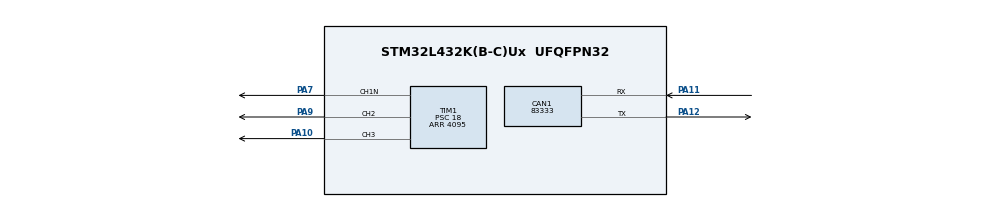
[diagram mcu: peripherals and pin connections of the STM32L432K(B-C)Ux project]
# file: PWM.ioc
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CAN1.CalculateBaudRate=83333
CAN1.CalculateTimeBit=12000
CAN1.CalculateTimeQuantum=4000.0
Mcu.Family=STM32L4
Mcu.Name=STM32L432K(B-C)Ux
Mcu.Package=UFQFPN32
NVIC.PriorityGroup=NVIC_PRIORITYGROUP_4
PA10.Signal=S_TIM1_CH3
PA11.Mode=CAN_Activate
PA11.Signal=CAN1_RX
PA12.Mode=CAN_Activate
PA12.Signal=CAN1_TX
PA7.Mode=PWM Generation1 CH1N
PA7.Signal=TIM1_CH1N
PA9.Signal=S_TIM1_CH2
ProjectManager.HeapSize=0x200
ProjectManager.StackSize=0x400
ProjectManager.TargetToolchain=STM32CubeIDE
RCC.APB1Freq_Value=4000000
RCC.APB1TimFreq_Value=4000000
RCC.APB2Freq_Value=4000000
RCC.APB2TimFreq_Value=4000000
RCC.HSE_VALUE=8000000
RCC.HSI48_VALUE=48000000
RCC.HSI_VALUE=16000000
RCC.MSI_VALUE=4000000
RCC.VCOOutputFreq_Value=32000000
SH.S_TIM1_CH2.0=TIM1_CH2,PWM Generation2 CH2
SH.S_TIM1_CH3.0=TIM1_CH3,PWM Generation3 CH3
TIM1.AutoReloadPreload=TIM_AUTORELOAD_PRELOAD_ENABLE
TIM1.Channel-PWM\ Generation1\ CH1N=TIM_CHANNEL_1
TIM1.Channel-PWM\ Generation2\ CH2=TIM_CHANNEL_2
TIM1.Channel-PWM\ Generation3\ CH3=TIM_CHANNEL_3
TIM1.Period=4095
TIM1.Prescaler=18
VP_TIM1_VS_ClockSourceINT.Mode=Internal
board=custom

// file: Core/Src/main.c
/* USER CODE BEGIN Header */
/**
  ******************************************************************************
  * @file           : main.c
  * @brief          : Main program body
  ******************************************************************************
  * @attention
  *
  * Copyright (c) 2023 STMicroelectronics.
  * All rights reserved.
  *
  * This software is licensed under terms that can be found in the LICENSE file
  * in the root directory of this software component.
  * If no LICENSE file comes with this software, it is provided AS-IS.
  *
  ******************************************************************************
  */
/* USER CODE END Header */
#include "main.h"

/* USER CODE BEGIN Includes */
#include "pwm.h"
#include "can.h"
/* USER CODE END Includes */

CAN_HandleTypeDef hcan1;

TIM_HandleTypeDef htim1;

void SystemClock_Config(void);
static void MX_GPIO_Init(void);
static void MX_TIM1_Init(void);
static void MX_CAN1_Init(void);

int main(void)
{

  /* MCU Configuration--------------------------------------------------------*/

  /* Reset of all peripherals, Initializes the Flash interface and the Systick. */
  HAL_Init();

  /* Configure the system clock */
  SystemClock_Config();

  /* Initialize all configured peripherals */
  MX_GPIO_Init();
  MX_TIM1_Init();
  MX_CAN1_Init();
  /* USER CODE BEGIN 2 */
  configure_CAN(&hcan1, CAN_ADDR_ACTIONNEUR_E);
  PWM_start_timer(TURBINE_CHANNEL);
  PWM_start_timer(SERVO_BALL_CHANNEL);
  PWM_start_timer(SERVO_BASKET_CHANNEL);

  /* USER CODE END 2 */

  /* Infinite loop */
  while (1)
  {

  }
}

void SystemClock_Config(void)
{
  RCC_OscInitTypeDef RCC_OscInitStruct = {0};
  RCC_ClkInitTypeDef RCC_ClkInitStruct = {0};

  /** Configure the main internal regulator output voltage
  */
  if (HAL_PWREx_ControlVoltageScaling(PWR_REGULATOR_VOLTAGE_SCALE1) != HAL_OK)
  {
    Error_Handler();
  }

  /** Initializes the RCC Oscillators according to the specified parameters
  * in the RCC_OscInitTypeDef structure.
  */
  RCC_OscInitStruct.OscillatorType = RCC_OSCILLATORTYPE_MSI;
  RCC_OscInitStruct.MSIState = RCC_MSI_ON;
  RCC_OscInitStruct.MSICalibrationValue = 0;
  RCC_OscInitStruct.MSIClockRange = RCC_MSIRANGE_6;
  RCC_OscInitStruct.PLL.PLLState = RCC_PLL_NONE;
  if (HAL_RCC_OscConfig(&RCC_OscInitStruct) != HAL_OK)
  {
    Error_Handler();
  }

  /** Initializes the CPU, AHB and APB buses clocks
  */
  RCC_ClkInitStruct.ClockType = RCC_CLOCKTYPE_HCLK|RCC_CLOCKTYPE_SYSCLK
                              |RCC_CLOCKTYPE_PCLK1|RCC_CLOCKTYPE_PCLK2;
  RCC_ClkInitStruct.SYSCLKSource = RCC_SYSCLKSOURCE_MSI;
  RCC_ClkInitStruct.AHBCLKDivider = RCC_SYSCLK_DIV1;
  RCC_ClkInitStruct.APB1CLKDivider = RCC_HCLK_DIV1;
  RCC_ClkInitStruct.APB2CLKDivider = RCC_HCLK_DIV1;

  if (HAL_RCC_ClockConfig(&RCC_ClkInitStruct, FLASH_LATENCY_0) != HAL_OK)
  {
    Error_Handler();
  }
}

static void MX_CAN1_Init(void)
{

  hcan1.Instance = CAN1;
  hcan1.Init.Prescaler = 16;
  hcan1.Init.Mode = CAN_MODE_NORMAL;
  hcan1.Init.SyncJumpWidth = CAN_SJW_1TQ;
  hcan1.Init.TimeSeg1 = CAN_BS1_1TQ;
  hcan1.Init.TimeSeg2 = CAN_BS2_1TQ;
  hcan1.Init.TimeTriggeredMode = DISABLE;
  hcan1.Init.AutoBusOff = DISABLE;
  hcan1.Init.AutoWakeUp = DISABLE;
  hcan1.Init.AutoRetransmission = DISABLE;
  hcan1.Init.ReceiveFifoLocked = DISABLE;
  hcan1.Init.TransmitFifoPriority = DISABLE;
  if (HAL_CAN_Init(&hcan1) != HAL_OK)
  {
    Error_Handler();
  }

}

static void MX_TIM1_Init(void)
{

  TIM_ClockConfigTypeDef sClockSourceConfig = {0};
  TIM_MasterConfigTypeDef sMasterConfig = {0};
  TIM_OC_InitTypeDef sConfigOC = {0};
  TIM_BreakDeadTimeConfigTypeDef sBreakDeadTimeConfig = {0};

  htim1.Instance = TIM1;
  htim1.Init.Prescaler = 18;
  htim1.Init.CounterMode = TIM_COUNTERMODE_UP;
  htim1.Init.Period = 4095;
  htim1.Init.ClockDivision = TIM_CLOCKDIVISION_DIV1;
  htim1.Init.RepetitionCounter = 0;
  htim1.Init.AutoReloadPreload = TIM_AUTORELOAD_PRELOAD_ENABLE;
  if (HAL_TIM_Base_Init(&htim1) != HAL_OK)
  {
    Error_Handler();
  }
  sClockSourceConfig.ClockSource = TIM_CLOCKSOURCE_INTERNAL;
  if (HAL_TIM_ConfigClockSource(&htim1, &sClockSourceConfig) != HAL_OK)
  {
    Error_Handler();
  }
  if (HAL_TIM_PWM_Init(&htim1) != HAL_OK)
  {
    Error_Handler();
  }
  sMasterConfig.MasterOutputTrigger = TIM_TRGO_RESET;
  sMasterConfig.MasterOutputTrigger2 = TIM_TRGO2_RESET;
  sMasterConfig.MasterSlaveMode = TIM_MASTERSLAVEMODE_DISABLE;
  if (HAL_TIMEx_MasterConfigSynchronization(&htim1, &sMasterConfig) != HAL_OK)
  {
    Error_Handler();
  }
  sConfigOC.OCMode = TIM_OCMODE_PWM1;
  sConfigOC.Pulse = 0;
  sConfigOC.OCPolarity = TIM_OCPOLARITY_HIGH;
  sConfigOC.OCNPolarity = TIM_OCNPOLARITY_HIGH;
  sConfigOC.OCFastMode = TIM_OCFAST_DISABLE;
  sConfigOC.OCIdleState = TIM_OCIDLESTATE_RESET;
  sConfigOC.OCNIdleState = TIM_OCNIDLESTATE_RESET;
  if (HAL_TIM_PWM_ConfigChannel(&htim1, &sConfigOC, TIM_CHANNEL_1) != HAL_OK)
  {
    Error_Handler();
  }
  if (HAL_TIM_PWM_ConfigChannel(&htim1, &sConfigOC, TIM_CHANNEL_2) != HAL_OK)
  {
    Error_Handler();
  }
  if (HAL_TIM_PWM_ConfigChannel(&htim1, &sConfigOC, TIM_CHANNEL_3) != HAL_OK)
  {
    Error_Handler();
  }
  sBreakDeadTimeConfig.OffStateRunMode = TIM_OSSR_DISABLE;
  sBreakDeadTimeConfig.OffStateIDLEMode = TIM_OSSI_DISABLE;
  sBreakDeadTimeConfig.LockLevel = TIM_LOCKLEVEL_OFF;
  sBreakDeadTimeConfig.DeadTime = 0;
  sBreakDeadTimeConfig.BreakState = TIM_BREAK_DISABLE;
  sBreakDeadTimeConfig.BreakPolarity = TIM_BREAKPOLARITY_HIGH;
  sBreakDeadTimeConfig.BreakFilter = 0;
  sBreakDeadTimeConfig.Break2State = TIM_BREAK2_DISABLE;
  sBreakDeadTimeConfig.Break2Polarity = TIM_BREAK2POLARITY_HIGH;
  sBreakDeadTimeConfig.Break2Filter = 0;
  sBreakDeadTimeConfig.AutomaticOutput = TIM_AUTOMATICOUTPUT_DISABLE;
  if (HAL_TIMEx_ConfigBreakDeadTime(&htim1, &sBreakDeadTimeConfig) != HAL_OK)
  {
    Error_Handler();
  }
  HAL_TIM_MspPostInit(&htim1);

}

static void MX_GPIO_Init(void)
{

  /* GPIO Ports Clock Enable */
  __HAL_RCC_GPIOA_CLK_ENABLE();

}

void Error_Handler(void)
{
  __disable_irq();
  while (1)
  {
  }
}
